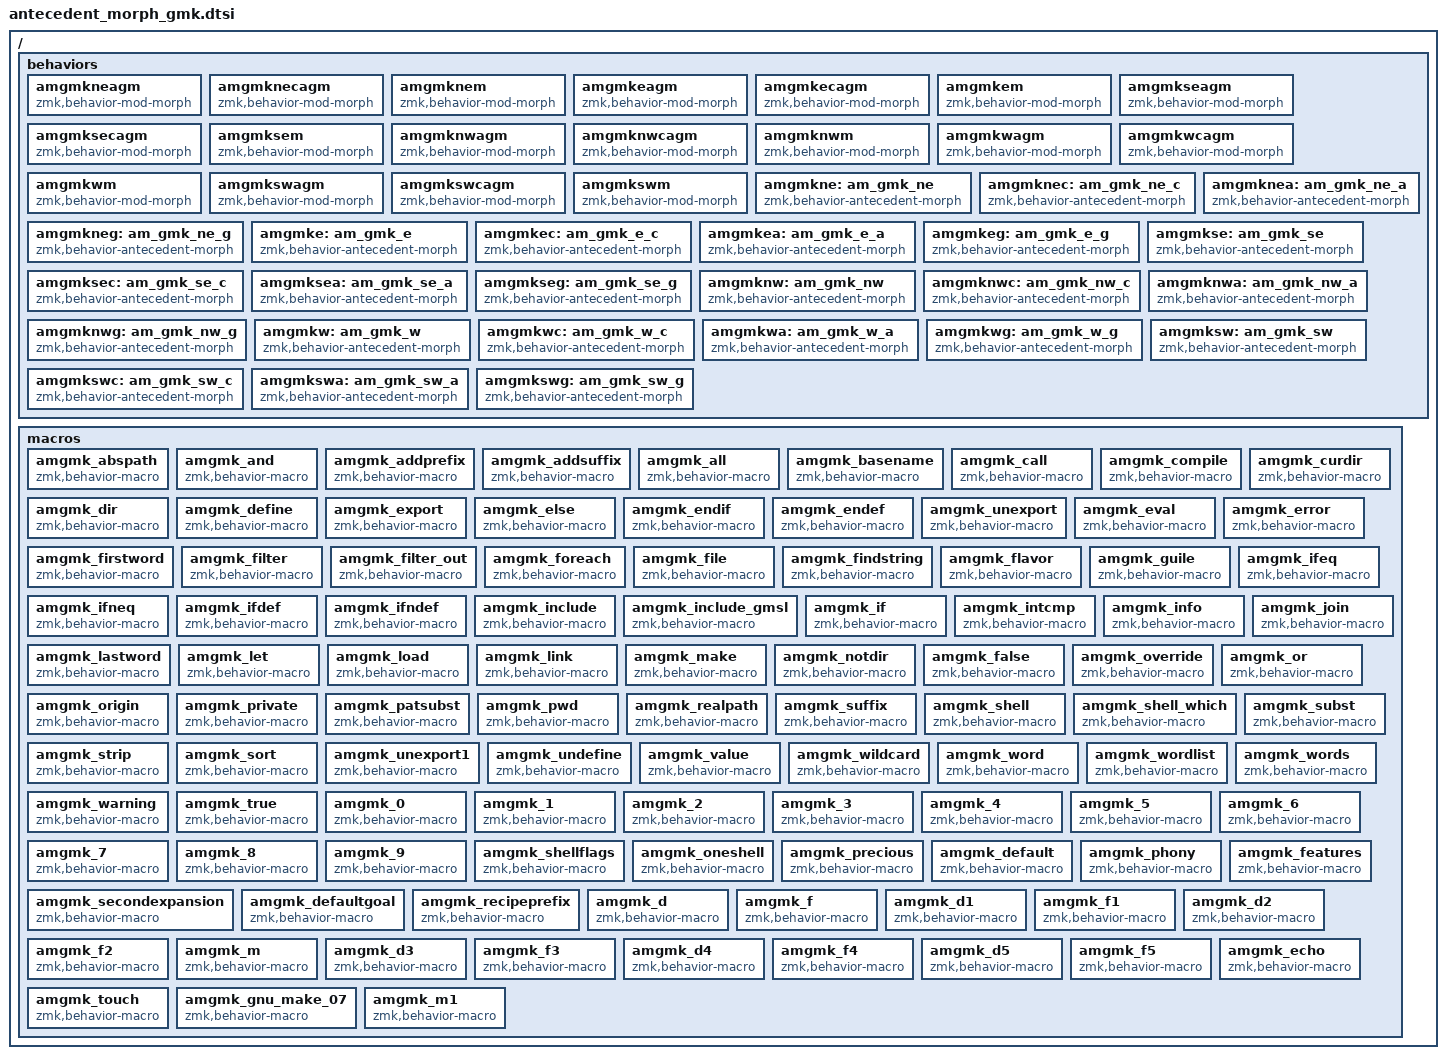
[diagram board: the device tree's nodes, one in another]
// GNU Make schema version 0.7
// Automatically generated by Antecedent Morph Configurator

/ {
    behaviors {
        // Mod-Morphs
        // Base layer
        // NE
        amgmkneagm: amgmkneagm {
            compatible = "zmk,behavior-mod-morph";
            #binding-cells = <0>;
            bindings = <&amgmknea>, <&amgmkneg>;
            mods = <(MOD_LGUI)>;
        };
        amgmknecagm: amgmknecagm {
            compatible = "zmk,behavior-mod-morph";
            #binding-cells = <0>;
            bindings = <&amgmknec>, <&amgmkneagm>;
            mods = <(MOD_LALT|MOD_LGUI)>;
        };
        amgmknem: amgmknem {
            compatible = "zmk,behavior-mod-morph";
            #binding-cells = <0>;
            bindings = <&amgmkne>, <&amgmknecagm>;
            mods = <(MOD_LCTL|MOD_LALT|MOD_LGUI)>;
        };
        // E
        amgmkeagm: amgmkeagm {
            compatible = "zmk,behavior-mod-morph";
            #binding-cells = <0>;
            bindings = <&amgmkea>, <&amgmkeg>;
            mods = <(MOD_LGUI)>;
        };
        amgmkecagm: amgmkecagm {
            compatible = "zmk,behavior-mod-morph";
            #binding-cells = <0>;
            bindings = <&amgmkec>, <&amgmkeagm>;
            mods = <(MOD_LALT|MOD_LGUI)>;
        };
        amgmkem: amgmkem {
            compatible = "zmk,behavior-mod-morph";
            #binding-cells = <0>;
            bindings = <&amgmke>, <&amgmkecagm>;
            mods = <(MOD_LCTL|MOD_LALT|MOD_LGUI)>;
        };
        // SE
        amgmkseagm: amgmkseagm {
            compatible = "zmk,behavior-mod-morph";
            #binding-cells = <0>;
            bindings = <&amgmksea>, <&amgmkseg>;
            mods = <(MOD_LGUI)>;
        };
        amgmksecagm: amgmksecagm {
            compatible = "zmk,behavior-mod-morph";
            #binding-cells = <0>;
            bindings = <&amgmksec>, <&amgmkseagm>;
            mods = <(MOD_LALT|MOD_LGUI)>;
        };
        amgmksem: amgmksem {
            compatible = "zmk,behavior-mod-morph";
            #binding-cells = <0>;
            bindings = <&amgmkse>, <&amgmksecagm>;
            mods = <(MOD_LCTL|MOD_LALT|MOD_LGUI)>;
        };
        // NW
        amgmknwagm: amgmknwagm {
            compatible = "zmk,behavior-mod-morph";
            #binding-cells = <0>;
            bindings = <&amgmknwa>, <&amgmknwg>;
            mods = <(MOD_RGUI)>;
        };
        amgmknwcagm: amgmknwcagm {
            compatible = "zmk,behavior-mod-morph";
            #binding-cells = <0>;
            bindings = <&amgmknwc>, <&amgmknwagm>;
            mods = <(MOD_RALT|MOD_RGUI)>;
        };
        amgmknwm: amgmknwm {
            compatible = "zmk,behavior-mod-morph";
            #binding-cells = <0>;
            bindings = <&amgmknw>, <&amgmknwcagm>;
            mods = <(MOD_RCTL|MOD_RALT|MOD_RGUI)>;
        };
        // W
        amgmkwagm: amgmkwagm {
            compatible = "zmk,behavior-mod-morph";
            #binding-cells = <0>;
            bindings = <&amgmkwa>, <&amgmkwg>;
            mods = <(MOD_RGUI)>;
        };
        amgmkwcagm: amgmkwcagm {
            compatible = "zmk,behavior-mod-morph";
            #binding-cells = <0>;
            bindings = <&amgmkwc>, <&amgmkwagm>;
            mods = <(MOD_RALT|MOD_RGUI)>;
        };
        amgmkwm: amgmkwm {
            compatible = "zmk,behavior-mod-morph";
            #binding-cells = <0>;
            bindings = <&amgmkw>, <&amgmkwcagm>;
            mods = <(MOD_RCTL|MOD_RALT|MOD_RGUI)>;
        };
        // SW
        amgmkswagm: amgmkswagm {
            compatible = "zmk,behavior-mod-morph";
            #binding-cells = <0>;
            bindings = <&amgmkswa>, <&amgmkswg>;
            mods = <(MOD_RGUI)>;
        };
        amgmkswcagm: amgmkswcagm {
            compatible = "zmk,behavior-mod-morph";
            #binding-cells = <0>;
            bindings = <&amgmkswc>, <&amgmkswagm>;
            mods = <(MOD_RALT|MOD_RGUI)>;
        };
        amgmkswm: amgmkswm {
            compatible = "zmk,behavior-mod-morph";
            #binding-cells = <0>;
            bindings = <&amgmksw>, <&amgmkswcagm>;
            mods = <(MOD_RCTL|MOD_RALT|MOD_RGUI)>;
        };
        // Antecedent Morphs
        amgmkne: am_gmk_ne {
            compatible = "zmk,behavior-antecedent-morph";
            label = "AM_GMK_NE";
            #binding-cells = <0>;
            defaults = <&none>;
            bindings = <&amgmk_abspath>, <&amgmk_basename>, <&amgmk_dir>, <&amgmk_export>, <&amgmk_firstword>, <&amgmk_ifeq>, <&amgmk_join>, <&amgmk_lastword>, <&amgmk_notdir>, <&amgmk_private>, <&amgmk_realpath>, <&amgmk_suffix>, <&amgmk_unexport1>, <&amgmk_wildcard>, <&amgmk_d>, <&amgmk_d1>, <&amgmk_d2>, <&kp EQUAL>, <&amgmk_d3>, <&amgmk_d4>, <&kp EQUAL>, <&kp EQUAL>, <&amgmk_d5>;
            antecedents = <A B D E F I J L N P R S U W SQT FSLH STAR COLON PRCNT CARET PLUS EXCL AT>;
            max-delay-ms = <U_ANTMORPH_DELAY>;
        };
        amgmknec: am_gmk_ne_c {
            compatible = "zmk,behavior-antecedent-morph";
            label = "AM_GMK_NE_C";
            #binding-cells = <0>;
            defaults = <&none>;
            bindings = <&amgmk_ifneq>, <&amgmk_f>, <&amgmk_f1>, <&amgmk_f2>, <&amgmk_f3>, <&amgmk_f4>, <&amgmk_f5>;
            antecedents = <I SQT FSLH STAR PRCNT CARET AT>;
            max-delay-ms = <U_ANTMORPH_DELAY>;
        };
        amgmknea: am_gmk_ne_a {
            compatible = "zmk,behavior-antecedent-morph";
            label = "AM_GMK_NE_A";
            #binding-cells = <0>;
            defaults = <&none>;
            bindings = <&none>;
            antecedents = <0x070100>;
            max-delay-ms = <U_ANTMORPH_DELAY>;
        };
        amgmkneg: am_gmk_ne_g {
            compatible = "zmk,behavior-antecedent-morph";
            label = "AM_GMK_NE_G";
            #binding-cells = <0>;
            defaults = <&none>;
            bindings = <&none>;
            antecedents = <0x070100>;
            max-delay-ms = <U_ANTMORPH_DELAY>;
        };
        amgmke: am_gmk_e {
            compatible = "zmk,behavior-antecedent-morph";
            label = "AM_GMK_E";
            #binding-cells = <0>;
            defaults = <&none>;
            bindings = <&amgmk_and>, <&amgmk_call>, <&amgmk_else>, <&amgmk_filter>, <&amgmk_guile>, <&amgmk_ifdef>, <&amgmk_let>, <&amgmk_patsubst>, <&amgmk_shell>, <&amgmk_value>, <&amgmk_word>, <&amgmk_0>, <&amgmk_1>, <&amgmk_2>, <&amgmk_3>, <&amgmk_4>, <&amgmk_5>, <&amgmk_6>, <&amgmk_7>, <&amgmk_8>, <&amgmk_9>, <&kp LPAR>, <&amgmk_echo>, <&amgmk_gnu_make_07>;
            antecedents = <A C E F G I L P S V W N0 N1 N2 N3 N4 N5 N6 N7 N8 N9 DLLR AT SPACE>;
            max-delay-ms = <U_ANTMORPH_DELAY>;
        };
        amgmkec: am_gmk_e_c {
            compatible = "zmk,behavior-antecedent-morph";
            label = "AM_GMK_E_C";
            #binding-cells = <0>;
            defaults = <&none>;
            bindings = <&amgmk_filter_out>, <&amgmk_ifndef>, <&amgmk_shell_which>, <&amgmk_wordlist>, <&amgmk_m>;
            antecedents = <F I S W DLLR>;
            max-delay-ms = <U_ANTMORPH_DELAY>;
        };
        amgmkea: am_gmk_e_a {
            compatible = "zmk,behavior-antecedent-morph";
            label = "AM_GMK_E_A";
            #binding-cells = <0>;
            defaults = <&none>;
            bindings = <&amgmk_words>;
            antecedents = <W>;
            max-delay-ms = <U_ANTMORPH_DELAY>;
        };
        amgmkeg: am_gmk_e_g {
            compatible = "zmk,behavior-antecedent-morph";
            label = "AM_GMK_E_G";
            #binding-cells = <0>;
            defaults = <&none>;
            bindings = <&none>;
            antecedents = <0x070100>;
            max-delay-ms = <U_ANTMORPH_DELAY>;
        };
        amgmkse: am_gmk_se {
            compatible = "zmk,behavior-antecedent-morph";
            label = "AM_GMK_SE";
            #binding-cells = <0>;
            defaults = <&none>;
            bindings = <&amgmk_addprefix>, <&amgmk_endif>, <&amgmk_foreach>, <&amgmk_load>, <&amgmk_override>, <&amgmk_subst>, <&amgmk_shellflags>, <&amgmk_touch>;
            antecedents = <A E F L O S DOT AT>;
            max-delay-ms = <U_ANTMORPH_DELAY>;
        };
        amgmksec: am_gmk_se_c {
            compatible = "zmk,behavior-antecedent-morph";
            label = "AM_GMK_SE_C";
            #binding-cells = <0>;
            defaults = <&none>;
            bindings = <&amgmk_addsuffix>, <&amgmk_oneshell>;
            antecedents = <A DOT>;
            max-delay-ms = <U_ANTMORPH_DELAY>;
        };
        amgmksea: am_gmk_se_a {
            compatible = "zmk,behavior-antecedent-morph";
            label = "AM_GMK_SE_A";
            #binding-cells = <0>;
            defaults = <&none>;
            bindings = <&none>;
            antecedents = <0x070100>;
            max-delay-ms = <U_ANTMORPH_DELAY>;
        };
        amgmkseg: am_gmk_se_g {
            compatible = "zmk,behavior-antecedent-morph";
            label = "AM_GMK_SE_G";
            #binding-cells = <0>;
            defaults = <&none>;
            bindings = <&none>;
            antecedents = <0x070100>;
            max-delay-ms = <U_ANTMORPH_DELAY>;
        };
        amgmknw: am_gmk_nw {
            compatible = "zmk,behavior-antecedent-morph";
            label = "AM_GMK_NW";
            #binding-cells = <0>;
            defaults = <&none>;
            bindings = <&amgmk_compile>, <&amgmk_define>, <&amgmk_endef>, <&amgmk_file>, <&amgmk_include>, <&amgmk_link>, <&amgmk_strip>, <&amgmk_undefine>, <&amgmk_precious>, <&kp EQUAL>;
            antecedents = <C D E F I L S U DOT FSLH>;
            max-delay-ms = <U_ANTMORPH_DELAY>;
        };
        amgmknwc: am_gmk_nw_c {
            compatible = "zmk,behavior-antecedent-morph";
            label = "AM_GMK_NW_C";
            #binding-cells = <0>;
            defaults = <&none>;
            bindings = <&amgmk_unexport>, <&amgmk_include_gmsl>, <&amgmk_default>;
            antecedents = <E I DOT>;
            max-delay-ms = <U_ANTMORPH_DELAY>;
        };
        amgmknwa: am_gmk_nw_a {
            compatible = "zmk,behavior-antecedent-morph";
            label = "AM_GMK_NW_A";
            #binding-cells = <0>;
            defaults = <&none>;
            bindings = <&none>;
            antecedents = <0x070100>;
            max-delay-ms = <U_ANTMORPH_DELAY>;
        };
        amgmknwg: am_gmk_nw_g {
            compatible = "zmk,behavior-antecedent-morph";
            label = "AM_GMK_NW_G";
            #binding-cells = <0>;
            defaults = <&none>;
            bindings = <&none>;
            antecedents = <0x070100>;
            max-delay-ms = <U_ANTMORPH_DELAY>;
        };
        amgmkw: am_gmk_w {
            compatible = "zmk,behavior-antecedent-morph";
            label = "AM_GMK_W";
            #binding-cells = <0>;
            defaults = <&none>;
            bindings = <&amgmk_all>, <&amgmk_curdir>, <&amgmk_eval>, <&amgmk_findstring>, <&amgmk_if>, <&amgmk_make>, <&amgmk_false>, <&amgmk_or>, <&amgmk_pwd>, <&amgmk_sort>, <&amgmk_true>, <&amgmk_phony>, <&kp MINUS>, <&amgmk_m1>;
            antecedents = <A C E F I M N O P S Y DOT AT SPACE>;
            max-delay-ms = <U_ANTMORPH_DELAY>;
        };
        amgmkwc: am_gmk_w_c {
            compatible = "zmk,behavior-antecedent-morph";
            label = "AM_GMK_W_C";
            #binding-cells = <0>;
            defaults = <&none>;
            bindings = <&amgmk_intcmp>, <&amgmk_features>;
            antecedents = <I DOT>;
            max-delay-ms = <U_ANTMORPH_DELAY>;
        };
        amgmkwa: am_gmk_w_a {
            compatible = "zmk,behavior-antecedent-morph";
            label = "AM_GMK_W_A";
            #binding-cells = <0>;
            defaults = <&none>;
            bindings = <&amgmk_secondexpansion>;
            antecedents = <DOT>;
            max-delay-ms = <U_ANTMORPH_DELAY>;
        };
        amgmkwg: am_gmk_w_g {
            compatible = "zmk,behavior-antecedent-morph";
            label = "AM_GMK_W_G";
            #binding-cells = <0>;
            defaults = <&none>;
            bindings = <&none>;
            antecedents = <0x070100>;
            max-delay-ms = <U_ANTMORPH_DELAY>;
        };
        amgmksw: am_gmk_sw {
            compatible = "zmk,behavior-antecedent-morph";
            label = "AM_GMK_SW";
            #binding-cells = <0>;
            defaults = <&none>;
            bindings = <&amgmk_error>, <&amgmk_flavor>, <&amgmk_info>, <&amgmk_origin>, <&amgmk_warning>, <&amgmk_defaultgoal>;
            antecedents = <E F I O W DOT>;
            max-delay-ms = <U_ANTMORPH_DELAY>;
        };
        amgmkswc: am_gmk_sw_c {
            compatible = "zmk,behavior-antecedent-morph";
            label = "AM_GMK_SW_C";
            #binding-cells = <0>;
            defaults = <&none>;
            bindings = <&amgmk_recipeprefix>;
            antecedents = <DOT>;
            max-delay-ms = <U_ANTMORPH_DELAY>;
        };
        amgmkswa: am_gmk_sw_a {
            compatible = "zmk,behavior-antecedent-morph";
            label = "AM_GMK_SW_A";
            #binding-cells = <0>;
            defaults = <&none>;
            bindings = <&none>;
            antecedents = <0x070100>;
            max-delay-ms = <U_ANTMORPH_DELAY>;
        };
        amgmkswg: am_gmk_sw_g {
            compatible = "zmk,behavior-antecedent-morph";
            label = "AM_GMK_SW_G";
            #binding-cells = <0>;
            defaults = <&none>;
            bindings = <&none>;
            antecedents = <0x070100>;
            max-delay-ms = <U_ANTMORPH_DELAY>;
        };
    };
    macros {
        // 'A'
        amgmk_abspath: amgmk_abspath {
            compatible = "zmk,behavior-macro";
            #binding-cells = <0>;
            wait-ms = <U_ANTMORPH_MACRO_WAIT>;
            tap-ms = <U_ANTMORPH_MACRO_TAP>;
            // [a]$(abspath 
            bindings = <&macro_tap &kp BSPC &kp DLLR &kp LPAR &kp A &kp B &kp S &kp P &kp A &kp T &kp H &kp SPACE>;
        };
        amgmk_and: amgmk_and {
            compatible = "zmk,behavior-macro";
            #binding-cells = <0>;
            wait-ms = <U_ANTMORPH_MACRO_WAIT>;
            tap-ms = <U_ANTMORPH_MACRO_TAP>;
            // [a]$(and 
            bindings = <&macro_tap &kp BSPC &kp DLLR &kp LPAR &kp A &kp N &kp D &kp SPACE>;
        };
        amgmk_addprefix: amgmk_addprefix {
            compatible = "zmk,behavior-macro";
            #binding-cells = <0>;
            wait-ms = <U_ANTMORPH_MACRO_WAIT>;
            tap-ms = <U_ANTMORPH_MACRO_TAP>;
            // [a]$(addprefix 
            bindings = <&macro_tap &kp BSPC &kp DLLR &kp LPAR &kp A &kp D &kp D &kp P &kp R &kp E &kp F &kp I &kp X &kp SPACE>;
        };
        amgmk_addsuffix: amgmk_addsuffix {
            compatible = "zmk,behavior-macro";
            #binding-cells = <0>;
            wait-ms = <U_ANTMORPH_MACRO_WAIT>;
            tap-ms = <U_ANTMORPH_MACRO_TAP>;
            // [a]$(addsuffix 
            bindings = <&macro_release &kp LCTRL>, <&macro_tap &kp BSPC &kp DLLR &kp LPAR &kp A &kp D &kp D &kp S &kp U &kp F &kp F &kp I &kp X &kp SPACE>;
        };
        amgmk_all: amgmk_all {
            compatible = "zmk,behavior-macro";
            #binding-cells = <0>;
            wait-ms = <U_ANTMORPH_MACRO_WAIT>;
            tap-ms = <U_ANTMORPH_MACRO_TAP>;
            // (a)ll: 
            bindings = <&macro_tap &kp L &kp L &kp COLON &kp SPACE>;
        };
        // 'B'
        amgmk_basename: amgmk_basename {
            compatible = "zmk,behavior-macro";
            #binding-cells = <0>;
            wait-ms = <U_ANTMORPH_MACRO_WAIT>;
            tap-ms = <U_ANTMORPH_MACRO_TAP>;
            // [b]$(basename 
            bindings = <&macro_tap &kp BSPC &kp DLLR &kp LPAR &kp B &kp A &kp S &kp E &kp N &kp A &kp M &kp E &kp SPACE>;
        };
        // 'C'
        amgmk_call: amgmk_call {
            compatible = "zmk,behavior-macro";
            #binding-cells = <0>;
            wait-ms = <U_ANTMORPH_MACRO_WAIT>;
            tap-ms = <U_ANTMORPH_MACRO_TAP>;
            // [c]$(call 
            bindings = <&macro_tap &kp BSPC &kp DLLR &kp LPAR &kp C &kp A &kp L &kp L &kp SPACE>;
        };
        amgmk_compile: amgmk_compile {
            compatible = "zmk,behavior-macro";
            #binding-cells = <0>;
            wait-ms = <U_ANTMORPH_MACRO_WAIT>;
            tap-ms = <U_ANTMORPH_MACRO_TAP>;
            // [c]$(COMPILE.
            bindings = <&macro_tap &kp BSPC &kp DLLR &kp LPAR &kp LS(C) &kp LS(O) &kp LS(M) &kp LS(P) &kp LS(I) &kp LS(L) &kp LS(E) &kp DOT>;
        };
        amgmk_curdir: amgmk_curdir {
            compatible = "zmk,behavior-macro";
            #binding-cells = <0>;
            wait-ms = <U_ANTMORPH_MACRO_WAIT>;
            tap-ms = <U_ANTMORPH_MACRO_TAP>;
            // [c]$(CURDIR)
            bindings = <&macro_tap &kp BSPC &kp DLLR &kp LPAR &kp LS(C) &kp LS(U) &kp LS(R) &kp LS(D) &kp LS(I) &kp LS(R) &kp RPAR>;
        };
        // 'D'
        amgmk_dir: amgmk_dir {
            compatible = "zmk,behavior-macro";
            #binding-cells = <0>;
            wait-ms = <U_ANTMORPH_MACRO_WAIT>;
            tap-ms = <U_ANTMORPH_MACRO_TAP>;
            // [d]$(dir 
            bindings = <&macro_tap &kp BSPC &kp DLLR &kp LPAR &kp D &kp I &kp R &kp SPACE>;
        };
        amgmk_define: amgmk_define {
            compatible = "zmk,behavior-macro";
            #binding-cells = <0>;
            wait-ms = <U_ANTMORPH_MACRO_WAIT>;
            tap-ms = <U_ANTMORPH_MACRO_TAP>;
            // (d)efine 
            bindings = <&macro_tap &kp E &kp F &kp I &kp N &kp E &kp SPACE>;
        };
        // 'E'
        amgmk_export: amgmk_export {
            compatible = "zmk,behavior-macro";
            #binding-cells = <0>;
            wait-ms = <U_ANTMORPH_MACRO_WAIT>;
            tap-ms = <U_ANTMORPH_MACRO_TAP>;
            // (e)xport 
            bindings = <&macro_tap &kp X &kp P &kp O &kp R &kp T &kp SPACE>;
        };
        amgmk_else: amgmk_else {
            compatible = "zmk,behavior-macro";
            #binding-cells = <0>;
            wait-ms = <U_ANTMORPH_MACRO_WAIT>;
            tap-ms = <U_ANTMORPH_MACRO_TAP>;
            // (e)lse
            bindings = <&macro_tap &kp L &kp S &kp E>;
        };
        amgmk_endif: amgmk_endif {
            compatible = "zmk,behavior-macro";
            #binding-cells = <0>;
            wait-ms = <U_ANTMORPH_MACRO_WAIT>;
            tap-ms = <U_ANTMORPH_MACRO_TAP>;
            // (e)ndif
            bindings = <&macro_tap &kp N &kp D &kp I &kp F>;
        };
        amgmk_endef: amgmk_endef {
            compatible = "zmk,behavior-macro";
            #binding-cells = <0>;
            wait-ms = <U_ANTMORPH_MACRO_WAIT>;
            tap-ms = <U_ANTMORPH_MACRO_TAP>;
            // (e)ndef
            bindings = <&macro_tap &kp N &kp D &kp E &kp F>;
        };
        amgmk_unexport: amgmk_unexport {
            compatible = "zmk,behavior-macro";
            #binding-cells = <0>;
            wait-ms = <U_ANTMORPH_MACRO_WAIT>;
            tap-ms = <U_ANTMORPH_MACRO_TAP>;
            // [e]unexport 
            bindings = <&macro_release &kp RCTRL>, <&macro_tap &kp BSPC &kp U &kp N &kp E &kp X &kp P &kp O &kp R &kp T &kp SPACE>;
        };
        amgmk_eval: amgmk_eval {
            compatible = "zmk,behavior-macro";
            #binding-cells = <0>;
            wait-ms = <U_ANTMORPH_MACRO_WAIT>;
            tap-ms = <U_ANTMORPH_MACRO_TAP>;
            // [e]$(eval 
            bindings = <&macro_tap &kp BSPC &kp DLLR &kp LPAR &kp E &kp V &kp A &kp L &kp SPACE>;
        };
        amgmk_error: amgmk_error {
            compatible = "zmk,behavior-macro";
            #binding-cells = <0>;
            wait-ms = <U_ANTMORPH_MACRO_WAIT>;
            tap-ms = <U_ANTMORPH_MACRO_TAP>;
            // [e]$(error 
            bindings = <&macro_tap &kp BSPC &kp DLLR &kp LPAR &kp E &kp R &kp R &kp O &kp R &kp SPACE>;
        };
        // 'F'
        amgmk_firstword: amgmk_firstword {
            compatible = "zmk,behavior-macro";
            #binding-cells = <0>;
            wait-ms = <U_ANTMORPH_MACRO_WAIT>;
            tap-ms = <U_ANTMORPH_MACRO_TAP>;
            // [f]$(firstword 
            bindings = <&macro_tap &kp BSPC &kp DLLR &kp LPAR &kp F &kp I &kp R &kp S &kp T &kp W &kp O &kp R &kp D &kp SPACE>;
        };
        amgmk_filter: amgmk_filter {
            compatible = "zmk,behavior-macro";
            #binding-cells = <0>;
            wait-ms = <U_ANTMORPH_MACRO_WAIT>;
            tap-ms = <U_ANTMORPH_MACRO_TAP>;
            // [f]$(filter 
            bindings = <&macro_tap &kp BSPC &kp DLLR &kp LPAR &kp F &kp I &kp L &kp T &kp E &kp R &kp SPACE>;
        };
        amgmk_filter_out: amgmk_filter_out {
            compatible = "zmk,behavior-macro";
            #binding-cells = <0>;
            wait-ms = <U_ANTMORPH_MACRO_WAIT>;
            tap-ms = <U_ANTMORPH_MACRO_TAP>;
            // [f]$(filter-out 
            bindings = <&macro_release &kp LCTRL>, <&macro_tap &kp BSPC &kp DLLR &kp LPAR &kp F &kp I &kp L &kp T &kp E &kp R &kp MINUS &kp O &kp U &kp T &kp SPACE>;
        };
        amgmk_foreach: amgmk_foreach {
            compatible = "zmk,behavior-macro";
            #binding-cells = <0>;
            wait-ms = <U_ANTMORPH_MACRO_WAIT>;
            tap-ms = <U_ANTMORPH_MACRO_TAP>;
            // [f]$(foreach 
            bindings = <&macro_tap &kp BSPC &kp DLLR &kp LPAR &kp F &kp O &kp R &kp E &kp A &kp C &kp H &kp SPACE>;
        };
        amgmk_file: amgmk_file {
            compatible = "zmk,behavior-macro";
            #binding-cells = <0>;
            wait-ms = <U_ANTMORPH_MACRO_WAIT>;
            tap-ms = <U_ANTMORPH_MACRO_TAP>;
            // [f]$(file 
            bindings = <&macro_tap &kp BSPC &kp DLLR &kp LPAR &kp F &kp I &kp L &kp E &kp SPACE>;
        };
        amgmk_findstring: amgmk_findstring {
            compatible = "zmk,behavior-macro";
            #binding-cells = <0>;
            wait-ms = <U_ANTMORPH_MACRO_WAIT>;
            tap-ms = <U_ANTMORPH_MACRO_TAP>;
            // [f]$(findstring 
            bindings = <&macro_tap &kp BSPC &kp DLLR &kp LPAR &kp F &kp I &kp N &kp D &kp S &kp T &kp R &kp I &kp N &kp G &kp SPACE>;
        };
        amgmk_flavor: amgmk_flavor {
            compatible = "zmk,behavior-macro";
            #binding-cells = <0>;
            wait-ms = <U_ANTMORPH_MACRO_WAIT>;
            tap-ms = <U_ANTMORPH_MACRO_TAP>;
            // [f]$(flavor 
            bindings = <&macro_tap &kp BSPC &kp DLLR &kp LPAR &kp F &kp L &kp A &kp V &kp O &kp R &kp SPACE>;
        };
        // 'G'
        amgmk_guile: amgmk_guile {
            compatible = "zmk,behavior-macro";
            #binding-cells = <0>;
            wait-ms = <U_ANTMORPH_MACRO_WAIT>;
            tap-ms = <U_ANTMORPH_MACRO_TAP>;
            // [g]$(guile 
            bindings = <&macro_tap &kp BSPC &kp DLLR &kp LPAR &kp G &kp U &kp I &kp L &kp E &kp SPACE>;
        };
        // 'I'
        amgmk_ifeq: amgmk_ifeq {
            compatible = "zmk,behavior-macro";
            #binding-cells = <0>;
            wait-ms = <U_ANTMORPH_MACRO_WAIT>;
            tap-ms = <U_ANTMORPH_MACRO_TAP>;
            // (i)feq 
            bindings = <&macro_tap &kp F &kp E &kp Q &kp SPACE>;
        };
        amgmk_ifneq: amgmk_ifneq {
            compatible = "zmk,behavior-macro";
            #binding-cells = <0>;
            wait-ms = <U_ANTMORPH_MACRO_WAIT>;
            tap-ms = <U_ANTMORPH_MACRO_TAP>;
            // (i)fneq 
            bindings = <&macro_release &kp LCTRL>, <&macro_tap &kp F &kp N &kp E &kp Q &kp SPACE>;
        };
        amgmk_ifdef: amgmk_ifdef {
            compatible = "zmk,behavior-macro";
            #binding-cells = <0>;
            wait-ms = <U_ANTMORPH_MACRO_WAIT>;
            tap-ms = <U_ANTMORPH_MACRO_TAP>;
            // (i)fdef 
            bindings = <&macro_tap &kp F &kp D &kp E &kp F &kp SPACE>;
        };
        amgmk_ifndef: amgmk_ifndef {
            compatible = "zmk,behavior-macro";
            #binding-cells = <0>;
            wait-ms = <U_ANTMORPH_MACRO_WAIT>;
            tap-ms = <U_ANTMORPH_MACRO_TAP>;
            // (i)fndef 
            bindings = <&macro_release &kp LCTRL>, <&macro_tap &kp F &kp N &kp D &kp E &kp F &kp SPACE>;
        };
        amgmk_include: amgmk_include {
            compatible = "zmk,behavior-macro";
            #binding-cells = <0>;
            wait-ms = <U_ANTMORPH_MACRO_WAIT>;
            tap-ms = <U_ANTMORPH_MACRO_TAP>;
            // (i)nclude 
            bindings = <&macro_tap &kp N &kp C &kp L &kp U &kp D &kp E &kp SPACE>;
        };
        amgmk_include_gmsl: amgmk_include_gmsl {
            compatible = "zmk,behavior-macro";
            #binding-cells = <0>;
            wait-ms = <U_ANTMORPH_MACRO_WAIT>;
            tap-ms = <U_ANTMORPH_MACRO_TAP>;
            // (i)nclude gmsl
            bindings = <&macro_release &kp RCTRL>, <&macro_tap &kp N &kp C &kp L &kp U &kp D &kp E &kp SPACE &kp G &kp M &kp S &kp L>;
        };
        amgmk_if: amgmk_if {
            compatible = "zmk,behavior-macro";
            #binding-cells = <0>;
            wait-ms = <U_ANTMORPH_MACRO_WAIT>;
            tap-ms = <U_ANTMORPH_MACRO_TAP>;
            // [i]$(if 
            bindings = <&macro_tap &kp BSPC &kp DLLR &kp LPAR &kp I &kp F &kp SPACE>;
        };
        amgmk_intcmp: amgmk_intcmp {
            compatible = "zmk,behavior-macro";
            #binding-cells = <0>;
            wait-ms = <U_ANTMORPH_MACRO_WAIT>;
            tap-ms = <U_ANTMORPH_MACRO_TAP>;
            // [i]$(intcmp 
            bindings = <&macro_release &kp RCTRL>, <&macro_tap &kp BSPC &kp DLLR &kp LPAR &kp I &kp N &kp T &kp C &kp M &kp P &kp SPACE>;
        };
        amgmk_info: amgmk_info {
            compatible = "zmk,behavior-macro";
            #binding-cells = <0>;
            wait-ms = <U_ANTMORPH_MACRO_WAIT>;
            tap-ms = <U_ANTMORPH_MACRO_TAP>;
            // [i]$(info 
            bindings = <&macro_tap &kp BSPC &kp DLLR &kp LPAR &kp I &kp N &kp F &kp O &kp SPACE>;
        };
        // 'J'
        amgmk_join: amgmk_join {
            compatible = "zmk,behavior-macro";
            #binding-cells = <0>;
            wait-ms = <U_ANTMORPH_MACRO_WAIT>;
            tap-ms = <U_ANTMORPH_MACRO_TAP>;
            // [j]$(join 
            bindings = <&macro_tap &kp BSPC &kp DLLR &kp LPAR &kp J &kp O &kp I &kp N &kp SPACE>;
        };
        // 'L'
        amgmk_lastword: amgmk_lastword {
            compatible = "zmk,behavior-macro";
            #binding-cells = <0>;
            wait-ms = <U_ANTMORPH_MACRO_WAIT>;
            tap-ms = <U_ANTMORPH_MACRO_TAP>;
            // [l]$(lastword 
            bindings = <&macro_tap &kp BSPC &kp DLLR &kp LPAR &kp L &kp A &kp S &kp T &kp W &kp O &kp R &kp D &kp SPACE>;
        };
        amgmk_let: amgmk_let {
            compatible = "zmk,behavior-macro";
            #binding-cells = <0>;
            wait-ms = <U_ANTMORPH_MACRO_WAIT>;
            tap-ms = <U_ANTMORPH_MACRO_TAP>;
            // [l]$(let 
            bindings = <&macro_tap &kp BSPC &kp DLLR &kp LPAR &kp L &kp E &kp T &kp SPACE>;
        };
        amgmk_load: amgmk_load {
            compatible = "zmk,behavior-macro";
            #binding-cells = <0>;
            wait-ms = <U_ANTMORPH_MACRO_WAIT>;
            tap-ms = <U_ANTMORPH_MACRO_TAP>;
            // (l)oad 
            bindings = <&macro_tap &kp O &kp A &kp D &kp SPACE>;
        };
        amgmk_link: amgmk_link {
            compatible = "zmk,behavior-macro";
            #binding-cells = <0>;
            wait-ms = <U_ANTMORPH_MACRO_WAIT>;
            tap-ms = <U_ANTMORPH_MACRO_TAP>;
            // [l]$(LINK.
            bindings = <&macro_tap &kp BSPC &kp DLLR &kp LPAR &kp LS(L) &kp LS(I) &kp LS(N) &kp LS(K) &kp DOT>;
        };
        // 'M'
        amgmk_make: amgmk_make {
            compatible = "zmk,behavior-macro";
            #binding-cells = <0>;
            wait-ms = <U_ANTMORPH_MACRO_WAIT>;
            tap-ms = <U_ANTMORPH_MACRO_TAP>;
            // [m]$(MAKE)
            bindings = <&macro_tap &kp BSPC &kp DLLR &kp LPAR &kp LS(M) &kp LS(A) &kp LS(K) &kp LS(E) &kp RPAR>;
        };
        // 'N'
        amgmk_notdir: amgmk_notdir {
            compatible = "zmk,behavior-macro";
            #binding-cells = <0>;
            wait-ms = <U_ANTMORPH_MACRO_WAIT>;
            tap-ms = <U_ANTMORPH_MACRO_TAP>;
            // [n]$(notdir 
            bindings = <&macro_tap &kp BSPC &kp DLLR &kp LPAR &kp N &kp O &kp T &kp D &kp I &kp R &kp SPACE>;
        };
        amgmk_false: amgmk_false {
            compatible = "zmk,behavior-macro";
            #binding-cells = <0>;
            wait-ms = <U_ANTMORPH_MACRO_WAIT>;
            tap-ms = <U_ANTMORPH_MACRO_TAP>;
            // [n]$(false)
            bindings = <&macro_tap &kp BSPC &kp DLLR &kp LPAR &kp F &kp A &kp L &kp S &kp E &kp RPAR>;
        };
        // 'O'
        amgmk_override: amgmk_override {
            compatible = "zmk,behavior-macro";
            #binding-cells = <0>;
            wait-ms = <U_ANTMORPH_MACRO_WAIT>;
            tap-ms = <U_ANTMORPH_MACRO_TAP>;
            // (o)verride 
            bindings = <&macro_tap &kp V &kp E &kp R &kp R &kp I &kp D &kp E &kp SPACE>;
        };
        amgmk_or: amgmk_or {
            compatible = "zmk,behavior-macro";
            #binding-cells = <0>;
            wait-ms = <U_ANTMORPH_MACRO_WAIT>;
            tap-ms = <U_ANTMORPH_MACRO_TAP>;
            // [o]$(or 
            bindings = <&macro_tap &kp BSPC &kp DLLR &kp LPAR &kp O &kp R &kp SPACE>;
        };
        amgmk_origin: amgmk_origin {
            compatible = "zmk,behavior-macro";
            #binding-cells = <0>;
            wait-ms = <U_ANTMORPH_MACRO_WAIT>;
            tap-ms = <U_ANTMORPH_MACRO_TAP>;
            // [o]$(origin 
            bindings = <&macro_tap &kp BSPC &kp DLLR &kp LPAR &kp O &kp R &kp I &kp G &kp I &kp N &kp SPACE>;
        };
        // 'P'
        amgmk_private: amgmk_private {
            compatible = "zmk,behavior-macro";
            #binding-cells = <0>;
            wait-ms = <U_ANTMORPH_MACRO_WAIT>;
            tap-ms = <U_ANTMORPH_MACRO_TAP>;
            // (p)rivate 
            bindings = <&macro_tap &kp R &kp I &kp V &kp A &kp T &kp E &kp SPACE>;
        };
        amgmk_patsubst: amgmk_patsubst {
            compatible = "zmk,behavior-macro";
            #binding-cells = <0>;
            wait-ms = <U_ANTMORPH_MACRO_WAIT>;
            tap-ms = <U_ANTMORPH_MACRO_TAP>;
            // [p]$(patsubst 
            bindings = <&macro_tap &kp BSPC &kp DLLR &kp LPAR &kp P &kp A &kp T &kp S &kp U &kp B &kp S &kp T &kp SPACE>;
        };
        amgmk_pwd: amgmk_pwd {
            compatible = "zmk,behavior-macro";
            #binding-cells = <0>;
            wait-ms = <U_ANTMORPH_MACRO_WAIT>;
            tap-ms = <U_ANTMORPH_MACRO_TAP>;
            // [p]$(PWD)
            bindings = <&macro_tap &kp BSPC &kp DLLR &kp LPAR &kp LS(P) &kp LS(W) &kp LS(D) &kp RPAR>;
        };
        // 'R'
        amgmk_realpath: amgmk_realpath {
            compatible = "zmk,behavior-macro";
            #binding-cells = <0>;
            wait-ms = <U_ANTMORPH_MACRO_WAIT>;
            tap-ms = <U_ANTMORPH_MACRO_TAP>;
            // [r]$(realpath 
            bindings = <&macro_tap &kp BSPC &kp DLLR &kp LPAR &kp R &kp E &kp A &kp L &kp P &kp A &kp T &kp H &kp SPACE>;
        };
        // 'S'
        amgmk_suffix: amgmk_suffix {
            compatible = "zmk,behavior-macro";
            #binding-cells = <0>;
            wait-ms = <U_ANTMORPH_MACRO_WAIT>;
            tap-ms = <U_ANTMORPH_MACRO_TAP>;
            // [s]$(suffix 
            bindings = <&macro_tap &kp BSPC &kp DLLR &kp LPAR &kp S &kp U &kp F &kp F &kp I &kp X &kp SPACE>;
        };
        amgmk_shell: amgmk_shell {
            compatible = "zmk,behavior-macro";
            #binding-cells = <0>;
            wait-ms = <U_ANTMORPH_MACRO_WAIT>;
            tap-ms = <U_ANTMORPH_MACRO_TAP>;
            // [s]$(shell 
            bindings = <&macro_tap &kp BSPC &kp DLLR &kp LPAR &kp S &kp H &kp E &kp L &kp L &kp SPACE>;
        };
        amgmk_shell_which: amgmk_shell_which {
            compatible = "zmk,behavior-macro";
            #binding-cells = <0>;
            wait-ms = <U_ANTMORPH_MACRO_WAIT>;
            tap-ms = <U_ANTMORPH_MACRO_TAP>;
            // [s]$(shell which 
            bindings = <&macro_release &kp LCTRL>, <&macro_tap &kp BSPC &kp DLLR &kp LPAR &kp S &kp H &kp E &kp L &kp L &kp SPACE &kp W &kp H &kp I &kp C &kp H &kp SPACE>;
        };
        amgmk_subst: amgmk_subst {
            compatible = "zmk,behavior-macro";
            #binding-cells = <0>;
            wait-ms = <U_ANTMORPH_MACRO_WAIT>;
            tap-ms = <U_ANTMORPH_MACRO_TAP>;
            // [s]$(subst 
            bindings = <&macro_tap &kp BSPC &kp DLLR &kp LPAR &kp S &kp U &kp B &kp S &kp T &kp SPACE>;
        };
        amgmk_strip: amgmk_strip {
            compatible = "zmk,behavior-macro";
            #binding-cells = <0>;
            wait-ms = <U_ANTMORPH_MACRO_WAIT>;
            tap-ms = <U_ANTMORPH_MACRO_TAP>;
            // [s]$(strip 
            bindings = <&macro_tap &kp BSPC &kp DLLR &kp LPAR &kp S &kp T &kp R &kp I &kp P &kp SPACE>;
        };
        amgmk_sort: amgmk_sort {
            compatible = "zmk,behavior-macro";
            #binding-cells = <0>;
            wait-ms = <U_ANTMORPH_MACRO_WAIT>;
            tap-ms = <U_ANTMORPH_MACRO_TAP>;
            // [s]$(sort 
            bindings = <&macro_tap &kp BSPC &kp DLLR &kp LPAR &kp S &kp O &kp R &kp T &kp SPACE>;
        };
        // 'U'
        amgmk_unexport1: amgmk_unexport1 {
            compatible = "zmk,behavior-macro";
            #binding-cells = <0>;
            wait-ms = <U_ANTMORPH_MACRO_WAIT>;
            tap-ms = <U_ANTMORPH_MACRO_TAP>;
            // (u)nexport 
            bindings = <&macro_tap &kp N &kp E &kp X &kp P &kp O &kp R &kp T &kp SPACE>;
        };
        amgmk_undefine: amgmk_undefine {
            compatible = "zmk,behavior-macro";
            #binding-cells = <0>;
            wait-ms = <U_ANTMORPH_MACRO_WAIT>;
            tap-ms = <U_ANTMORPH_MACRO_TAP>;
            // (u)ndefine 
            bindings = <&macro_tap &kp N &kp D &kp E &kp F &kp I &kp N &kp E &kp SPACE>;
        };
        // 'V'
        amgmk_value: amgmk_value {
            compatible = "zmk,behavior-macro";
            #binding-cells = <0>;
            wait-ms = <U_ANTMORPH_MACRO_WAIT>;
            tap-ms = <U_ANTMORPH_MACRO_TAP>;
            // [v]$(value 
            bindings = <&macro_tap &kp BSPC &kp DLLR &kp LPAR &kp V &kp A &kp L &kp U &kp E &kp SPACE>;
        };
        // 'W'
        amgmk_wildcard: amgmk_wildcard {
            compatible = "zmk,behavior-macro";
            #binding-cells = <0>;
            wait-ms = <U_ANTMORPH_MACRO_WAIT>;
            tap-ms = <U_ANTMORPH_MACRO_TAP>;
            // [w]$(wildcard 
            bindings = <&macro_tap &kp BSPC &kp DLLR &kp LPAR &kp W &kp I &kp L &kp D &kp C &kp A &kp R &kp D &kp SPACE>;
        };
        amgmk_word: amgmk_word {
            compatible = "zmk,behavior-macro";
            #binding-cells = <0>;
            wait-ms = <U_ANTMORPH_MACRO_WAIT>;
            tap-ms = <U_ANTMORPH_MACRO_TAP>;
            // [w]$(word 
            bindings = <&macro_tap &kp BSPC &kp DLLR &kp LPAR &kp W &kp O &kp R &kp D &kp SPACE>;
        };
        amgmk_wordlist: amgmk_wordlist {
            compatible = "zmk,behavior-macro";
            #binding-cells = <0>;
            wait-ms = <U_ANTMORPH_MACRO_WAIT>;
            tap-ms = <U_ANTMORPH_MACRO_TAP>;
            // [w]$(wordlist 
            bindings = <&macro_release &kp LCTRL>, <&macro_tap &kp BSPC &kp DLLR &kp LPAR &kp W &kp O &kp R &kp D &kp L &kp I &kp S &kp T &kp SPACE>;
        };
        amgmk_words: amgmk_words {
            compatible = "zmk,behavior-macro";
            #binding-cells = <0>;
            wait-ms = <U_ANTMORPH_MACRO_WAIT>;
            tap-ms = <U_ANTMORPH_MACRO_TAP>;
            // [w]$(words 
            bindings = <&macro_release &kp LALT>, <&macro_tap &kp LALT>, <&macro_tap &kp BSPC &kp DLLR &kp LPAR &kp W &kp O &kp R &kp D &kp S &kp SPACE>;
        };
        amgmk_warning: amgmk_warning {
            compatible = "zmk,behavior-macro";
            #binding-cells = <0>;
            wait-ms = <U_ANTMORPH_MACRO_WAIT>;
            tap-ms = <U_ANTMORPH_MACRO_TAP>;
            // [w]$(warning 
            bindings = <&macro_tap &kp BSPC &kp DLLR &kp LPAR &kp W &kp A &kp R &kp N &kp I &kp N &kp G &kp SPACE>;
        };
        // 'Y'
        amgmk_true: amgmk_true {
            compatible = "zmk,behavior-macro";
            #binding-cells = <0>;
            wait-ms = <U_ANTMORPH_MACRO_WAIT>;
            tap-ms = <U_ANTMORPH_MACRO_TAP>;
            // [y]$(true)
            bindings = <&macro_tap &kp BSPC &kp DLLR &kp LPAR &kp T &kp R &kp U &kp E &kp RPAR>;
        };
        // '0'
        amgmk_0: amgmk_0 {
            compatible = "zmk,behavior-macro";
            #binding-cells = <0>;
            wait-ms = <U_ANTMORPH_MACRO_WAIT>;
            tap-ms = <U_ANTMORPH_MACRO_TAP>;
            // [0]$0
            bindings = <&macro_tap &kp BSPC &kp DLLR &kp N0>;
        };
        // '1'
        amgmk_1: amgmk_1 {
            compatible = "zmk,behavior-macro";
            #binding-cells = <0>;
            wait-ms = <U_ANTMORPH_MACRO_WAIT>;
            tap-ms = <U_ANTMORPH_MACRO_TAP>;
            // [1]$1
            bindings = <&macro_tap &kp BSPC &kp DLLR &kp N1>;
        };
        // '2'
        amgmk_2: amgmk_2 {
            compatible = "zmk,behavior-macro";
            #binding-cells = <0>;
            wait-ms = <U_ANTMORPH_MACRO_WAIT>;
            tap-ms = <U_ANTMORPH_MACRO_TAP>;
            // [2]$2
            bindings = <&macro_tap &kp BSPC &kp DLLR &kp N2>;
        };
        // '3'
        amgmk_3: amgmk_3 {
            compatible = "zmk,behavior-macro";
            #binding-cells = <0>;
            wait-ms = <U_ANTMORPH_MACRO_WAIT>;
            tap-ms = <U_ANTMORPH_MACRO_TAP>;
            // [3]$3
            bindings = <&macro_tap &kp BSPC &kp DLLR &kp N3>;
        };
        // '4'
        amgmk_4: amgmk_4 {
            compatible = "zmk,behavior-macro";
            #binding-cells = <0>;
            wait-ms = <U_ANTMORPH_MACRO_WAIT>;
            tap-ms = <U_ANTMORPH_MACRO_TAP>;
            // [4]$4
            bindings = <&macro_tap &kp BSPC &kp DLLR &kp N4>;
        };
        // '5'
        amgmk_5: amgmk_5 {
            compatible = "zmk,behavior-macro";
            #binding-cells = <0>;
            wait-ms = <U_ANTMORPH_MACRO_WAIT>;
            tap-ms = <U_ANTMORPH_MACRO_TAP>;
            // [5]$5
            bindings = <&macro_tap &kp BSPC &kp DLLR &kp N5>;
        };
        // '6'
        amgmk_6: amgmk_6 {
            compatible = "zmk,behavior-macro";
            #binding-cells = <0>;
            wait-ms = <U_ANTMORPH_MACRO_WAIT>;
            tap-ms = <U_ANTMORPH_MACRO_TAP>;
            // [6]$6
            bindings = <&macro_tap &kp BSPC &kp DLLR &kp N6>;
        };
        // '7'
        amgmk_7: amgmk_7 {
            compatible = "zmk,behavior-macro";
            #binding-cells = <0>;
            wait-ms = <U_ANTMORPH_MACRO_WAIT>;
            tap-ms = <U_ANTMORPH_MACRO_TAP>;
            // [7]$7
            bindings = <&macro_tap &kp BSPC &kp DLLR &kp N7>;
        };
        // '8'
        amgmk_8: amgmk_8 {
            compatible = "zmk,behavior-macro";
            #binding-cells = <0>;
            wait-ms = <U_ANTMORPH_MACRO_WAIT>;
            tap-ms = <U_ANTMORPH_MACRO_TAP>;
            // [8]$8
            bindings = <&macro_tap &kp BSPC &kp DLLR &kp N8>;
        };
        // '9'
        amgmk_9: amgmk_9 {
            compatible = "zmk,behavior-macro";
            #binding-cells = <0>;
            wait-ms = <U_ANTMORPH_MACRO_WAIT>;
            tap-ms = <U_ANTMORPH_MACRO_TAP>;
            // [9]$9
            bindings = <&macro_tap &kp BSPC &kp DLLR &kp N9>;
        };
        // '.'
        amgmk_shellflags: amgmk_shellflags {
            compatible = "zmk,behavior-macro";
            #binding-cells = <0>;
            wait-ms = <U_ANTMORPH_MACRO_WAIT>;
            tap-ms = <U_ANTMORPH_MACRO_TAP>;
            // (.)SHELLFLAGS =
            bindings = <&macro_tap &kp LS(S) &kp LS(H) &kp LS(E) &kp LS(L) &kp LS(L) &kp LS(F) &kp LS(L) &kp LS(A) &kp LS(G) &kp LS(S) &kp SPACE &kp EQUAL>;
        };
        amgmk_oneshell: amgmk_oneshell {
            compatible = "zmk,behavior-macro";
            #binding-cells = <0>;
            wait-ms = <U_ANTMORPH_MACRO_WAIT>;
            tap-ms = <U_ANTMORPH_MACRO_TAP>;
            // (.)ONESHELL:
            bindings = <&macro_release &kp LCTRL>, <&macro_tap &kp LS(O) &kp LS(N) &kp LS(E) &kp LS(S) &kp LS(H) &kp LS(E) &kp LS(L) &kp LS(L) &kp COLON>;
        };
        amgmk_precious: amgmk_precious {
            compatible = "zmk,behavior-macro";
            #binding-cells = <0>;
            wait-ms = <U_ANTMORPH_MACRO_WAIT>;
            tap-ms = <U_ANTMORPH_MACRO_TAP>;
            // (.)PRECIOUS:
            bindings = <&macro_tap &kp LS(P) &kp LS(R) &kp LS(E) &kp LS(C) &kp LS(I) &kp LS(O) &kp LS(U) &kp LS(S) &kp COLON>;
        };
        amgmk_default: amgmk_default {
            compatible = "zmk,behavior-macro";
            #binding-cells = <0>;
            wait-ms = <U_ANTMORPH_MACRO_WAIT>;
            tap-ms = <U_ANTMORPH_MACRO_TAP>;
            // (.)DEFAULT:
            bindings = <&macro_release &kp RCTRL>, <&macro_tap &kp LS(D) &kp LS(E) &kp LS(F) &kp LS(A) &kp LS(U) &kp LS(L) &kp LS(T) &kp COLON>;
        };
        amgmk_phony: amgmk_phony {
            compatible = "zmk,behavior-macro";
            #binding-cells = <0>;
            wait-ms = <U_ANTMORPH_MACRO_WAIT>;
            tap-ms = <U_ANTMORPH_MACRO_TAP>;
            // (.)PHONY: 
            bindings = <&macro_tap &kp LS(P) &kp LS(H) &kp LS(O) &kp LS(N) &kp LS(Y) &kp COLON &kp SPACE>;
        };
        amgmk_features: amgmk_features {
            compatible = "zmk,behavior-macro";
            #binding-cells = <0>;
            wait-ms = <U_ANTMORPH_MACRO_WAIT>;
            tap-ms = <U_ANTMORPH_MACRO_TAP>;
            // (.)FEATURES
            bindings = <&macro_release &kp RCTRL>, <&macro_tap &kp LS(F) &kp LS(E) &kp LS(A) &kp LS(T) &kp LS(U) &kp LS(R) &kp LS(E) &kp LS(S)>;
        };
        amgmk_secondexpansion: amgmk_secondexpansion {
            compatible = "zmk,behavior-macro";
            #binding-cells = <0>;
            wait-ms = <U_ANTMORPH_MACRO_WAIT>;
            tap-ms = <U_ANTMORPH_MACRO_TAP>;
            // (.)SECONDEXPANSION:
            bindings = <&macro_release &kp RALT>, <&macro_tap &kp RALT>, <&macro_tap &kp LS(S) &kp LS(E) &kp LS(C) &kp LS(O) &kp LS(N) &kp LS(D) &kp LS(E) &kp LS(X) &kp LS(P) &kp LS(A) &kp LS(N) &kp LS(S) &kp LS(I) &kp LS(O) &kp LS(N) &kp COLON>;
        };
        amgmk_defaultgoal: amgmk_defaultgoal {
            compatible = "zmk,behavior-macro";
            #binding-cells = <0>;
            wait-ms = <U_ANTMORPH_MACRO_WAIT>;
            tap-ms = <U_ANTMORPH_MACRO_TAP>;
            // (.)DEFAULT_GOAL := 
            bindings = <&macro_tap &kp LS(D) &kp LS(E) &kp LS(F) &kp LS(A) &kp LS(U) &kp LS(L) &kp LS(T) &kp UNDER &kp LS(G) &kp LS(O) &kp LS(A) &kp LS(L) &kp SPACE &kp COLON &kp EQUAL &kp SPACE>;
        };
        amgmk_recipeprefix: amgmk_recipeprefix {
            compatible = "zmk,behavior-macro";
            #binding-cells = <0>;
            wait-ms = <U_ANTMORPH_MACRO_WAIT>;
            tap-ms = <U_ANTMORPH_MACRO_TAP>;
            // (.)RECIPEPREFIX = 
            bindings = <&macro_release &kp RCTRL>, <&macro_tap &kp LS(R) &kp LS(E) &kp LS(C) &kp LS(I) &kp LS(P) &kp LS(E) &kp LS(P) &kp LS(R) &kp LS(E) &kp LS(F) &kp LS(I) &kp LS(X) &kp SPACE &kp EQUAL &kp SPACE>;
        };
        // '''
        amgmk_d: amgmk_d {
            compatible = "zmk,behavior-macro";
            #binding-cells = <0>;
            wait-ms = <U_ANTMORPH_MACRO_WAIT>;
            tap-ms = <U_ANTMORPH_MACRO_TAP>;
            // [']$(<D)
            bindings = <&macro_tap &kp BSPC &kp DLLR &kp LPAR &kp LT &kp LS(D) &kp RPAR>;
        };
        amgmk_f: amgmk_f {
            compatible = "zmk,behavior-macro";
            #binding-cells = <0>;
            wait-ms = <U_ANTMORPH_MACRO_WAIT>;
            tap-ms = <U_ANTMORPH_MACRO_TAP>;
            // [']$(<F)
            bindings = <&macro_release &kp LCTRL>, <&macro_tap &kp BSPC &kp DLLR &kp LPAR &kp LT &kp LS(F) &kp RPAR>;
        };
        // '/'
        amgmk_d1: amgmk_d1 {
            compatible = "zmk,behavior-macro";
            #binding-cells = <0>;
            wait-ms = <U_ANTMORPH_MACRO_WAIT>;
            tap-ms = <U_ANTMORPH_MACRO_TAP>;
            // [/]$(?D)
            bindings = <&macro_tap &kp BSPC &kp DLLR &kp LPAR &kp QMARK &kp LS(D) &kp RPAR>;
        };
        amgmk_f1: amgmk_f1 {
            compatible = "zmk,behavior-macro";
            #binding-cells = <0>;
            wait-ms = <U_ANTMORPH_MACRO_WAIT>;
            tap-ms = <U_ANTMORPH_MACRO_TAP>;
            // [/]$(?F)
            bindings = <&macro_release &kp LCTRL>, <&macro_tap &kp BSPC &kp DLLR &kp LPAR &kp QMARK &kp LS(F) &kp RPAR>;
        };
        // '*'
        amgmk_d2: amgmk_d2 {
            compatible = "zmk,behavior-macro";
            #binding-cells = <0>;
            wait-ms = <U_ANTMORPH_MACRO_WAIT>;
            tap-ms = <U_ANTMORPH_MACRO_TAP>;
            // [*]$(*D)
            bindings = <&macro_tap &kp BSPC &kp DLLR &kp LPAR &kp STAR &kp LS(D) &kp RPAR>;
        };
        amgmk_f2: amgmk_f2 {
            compatible = "zmk,behavior-macro";
            #binding-cells = <0>;
            wait-ms = <U_ANTMORPH_MACRO_WAIT>;
            tap-ms = <U_ANTMORPH_MACRO_TAP>;
            // [*]$(*F)
            bindings = <&macro_release &kp LCTRL>, <&macro_tap &kp BSPC &kp DLLR &kp LPAR &kp STAR &kp LS(F) &kp RPAR>;
        };
        // '$'
        amgmk_m: amgmk_m {
            compatible = "zmk,behavior-macro";
            #binding-cells = <0>;
            wait-ms = <U_ANTMORPH_MACRO_WAIT>;
            tap-ms = <U_ANTMORPH_MACRO_TAP>;
            // ($)(__
            bindings = <&macro_release &kp LCTRL>, <&macro_tap &kp LPAR &kp UNDER &kp UNDER>;
        };
        // '%'
        amgmk_d3: amgmk_d3 {
            compatible = "zmk,behavior-macro";
            #binding-cells = <0>;
            wait-ms = <U_ANTMORPH_MACRO_WAIT>;
            tap-ms = <U_ANTMORPH_MACRO_TAP>;
            // [%]$(%D)
            bindings = <&macro_tap &kp BSPC &kp DLLR &kp LPAR &kp PRCNT &kp LS(D) &kp RPAR>;
        };
        amgmk_f3: amgmk_f3 {
            compatible = "zmk,behavior-macro";
            #binding-cells = <0>;
            wait-ms = <U_ANTMORPH_MACRO_WAIT>;
            tap-ms = <U_ANTMORPH_MACRO_TAP>;
            // [%]$(%F)
            bindings = <&macro_release &kp LCTRL>, <&macro_tap &kp BSPC &kp DLLR &kp LPAR &kp PRCNT &kp LS(F) &kp RPAR>;
        };
        // '^'
        amgmk_d4: amgmk_d4 {
            compatible = "zmk,behavior-macro";
            #binding-cells = <0>;
            wait-ms = <U_ANTMORPH_MACRO_WAIT>;
            tap-ms = <U_ANTMORPH_MACRO_TAP>;
            // [^]$(^D)
            bindings = <&macro_tap &kp BSPC &kp DLLR &kp LPAR &kp CARET &kp LS(D) &kp RPAR>;
        };
        amgmk_f4: amgmk_f4 {
            compatible = "zmk,behavior-macro";
            #binding-cells = <0>;
            wait-ms = <U_ANTMORPH_MACRO_WAIT>;
            tap-ms = <U_ANTMORPH_MACRO_TAP>;
            // [^]$(^F)
            bindings = <&macro_release &kp LCTRL>, <&macro_tap &kp BSPC &kp DLLR &kp LPAR &kp CARET &kp LS(F) &kp RPAR>;
        };
        // '@'
        amgmk_d5: amgmk_d5 {
            compatible = "zmk,behavior-macro";
            #binding-cells = <0>;
            wait-ms = <U_ANTMORPH_MACRO_WAIT>;
            tap-ms = <U_ANTMORPH_MACRO_TAP>;
            // [@]$(@D)
            bindings = <&macro_tap &kp BSPC &kp DLLR &kp LPAR &kp AT &kp LS(D) &kp RPAR>;
        };
        amgmk_f5: amgmk_f5 {
            compatible = "zmk,behavior-macro";
            #binding-cells = <0>;
            wait-ms = <U_ANTMORPH_MACRO_WAIT>;
            tap-ms = <U_ANTMORPH_MACRO_TAP>;
            // [@]$(@F)
            bindings = <&macro_release &kp LCTRL>, <&macro_tap &kp BSPC &kp DLLR &kp LPAR &kp AT &kp LS(F) &kp RPAR>;
        };
        amgmk_echo: amgmk_echo {
            compatible = "zmk,behavior-macro";
            #binding-cells = <0>;
            wait-ms = <U_ANTMORPH_MACRO_WAIT>;
            tap-ms = <U_ANTMORPH_MACRO_TAP>;
            // (@)echo 
            bindings = <&macro_tap &kp E &kp C &kp H &kp O &kp SPACE>;
        };
        amgmk_touch: amgmk_touch {
            compatible = "zmk,behavior-macro";
            #binding-cells = <0>;
            wait-ms = <U_ANTMORPH_MACRO_WAIT>;
            tap-ms = <U_ANTMORPH_MACRO_TAP>;
            // (@)touch 
            bindings = <&macro_tap &kp T &kp O &kp U &kp C &kp H &kp SPACE>;
        };
        // ' '
        amgmk_gnu_make_07: amgmk_gnu_make_07 {
            compatible = "zmk,behavior-macro";
            #binding-cells = <0>;
            wait-ms = <U_ANTMORPH_MACRO_WAIT>;
            tap-ms = <U_ANTMORPH_MACRO_TAP>;
            // [ ]GNU Make 0.7
            bindings = <&macro_tap &kp BSPC &kp LS(G) &kp LS(N) &kp LS(U) &kp SPACE &kp LS(M) &kp A &kp K &kp E &kp SPACE &kp N0 &kp DOT &kp N7>;
        };
        amgmk_m1: amgmk_m1 {
            compatible = "zmk,behavior-macro";
            #binding-cells = <0>;
            wait-ms = <U_ANTMORPH_MACRO_WAIT>;
            tap-ms = <U_ANTMORPH_MACRO_TAP>;
            // [ ]\ ·
            bindings = <&macro_tap &kp BSPC &kp BSLH &kp SPACE>;
        };
    };
};
